AUTOSAR XML (schema 4-0-3)
package /ComponentTypes
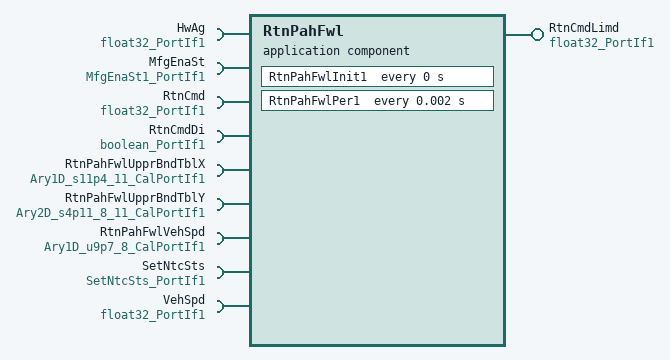
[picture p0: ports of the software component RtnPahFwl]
  application sw component type RtnPahFwl
    provide port RtnCmdLimd: nonqueued-sender-com-spec{data-element=Val, init-value=0}, provided-interface=float32_PortIf1
    9 x require port:
      HwAg: nonqueued-receiver-com-spec{data-element=Val, filter=data-filter-type=ALWAYS, init-value=0}, required-interface=float32_PortIf1
      MfgEnaSt: nonqueued-receiver-com-spec{data-element=Val, filter=data-filter-type=ALWAYS, init-value=0}, required-interface=MfgEnaSt1_PortIf1
      RtnCmd: nonqueued-receiver-com-spec{data-element=Val, filter=data-filter-type=ALWAYS, init-value=0}, required-interface=float32_PortIf1
      RtnCmdDi: nonqueued-receiver-com-spec{data-element=Logl, filter=data-filter-type=ALWAYS, init-value=0}, required-interface=boolean_PortIf1
      RtnPahFwlUpprBndTblX: parameter-require-com-spec{init-value=[-6400, -1600, 0, 800, 1600, 2400, 3200, 4000, 4800, 5600, 6400], parameter=Ary1D}, required-interface=Ary1D_s11p4_11_CalPortIf1
      RtnPahFwlUpprBndTblY: parameter-require-com-spec{init-value=8 x 11 x 18022, parameter=Ary2D}, required-interface=Ary2D_s4p11_8_11_CalPortIf1
      RtnPahFwlVehSpd: parameter-require-com-spec{init-value=[0, 384, 1280, 2560, 3840, 7680, 12800, 32640], parameter=Ary1D}, required-interface=Ary1D_u9p7_8_CalPortIf1
      SetNtcSts: client-com-spec=Oper, required-interface=SetNtcSts_PortIf1
      VehSpd: nonqueued-receiver-com-spec{data-element=Val, filter=data-filter-type=ALWAYS, init-value=0}, required-interface=float32_PortIf1
    behavior RtnPahFwl_InternalBehavior
      ar-typed-per-instance-memorys:
        data dRtnPahFwlLowrBnd: sw-calibration-access=READ-ONLY, type=float32
        data dRtnPahFwlOverBnd: sw-calibration-access=READ-ONLY, type=boolean
        data dRtnPahFwlUpprBnd: sw-calibration-access=READ-ONLY, type=float32
      timing event RtnPahFwlInit1_InitEvent: start-on-event=RtnPahFwlInit1, period=0
      timing event TMT_RtnPahFwlPer1: start-on-event=RtnPahFwlPer1, period=0.002
      runnable RtnPahFwlInit1
        sync call SC_SetNtcSts_Oper: operation=SetNtcSts.Oper, timeout=0
      runnable RtnPahFwlPer1: minimum-start-interval=0.002
        data-receive-point-by-arguments:
          5 x access:
            REC_HwAg_Val: accessed-variable=HwAg.Val
            REC_RtnCmd_Val: accessed-variable=RtnCmd.Val
            REC_RtnCmdDi_Logl: accessed-variable=RtnCmdDi.Logl
            REC_VehSpd_Val: accessed-variable=VehSpd.Val
            SEND_MfgEnaSt_Val: accessed-variable=MfgEnaSt.Val
        data-send-points:
          access SEND_RtnCmdLimd_Val: accessed-variable=RtnCmdLimd.Val
        sync call SC_SetNtcSts_Oper: operation=SetNtcSts.Oper, timeout=0
  swc implementation RtnPahFwl_Implementation: behavior=RtnPahFwl_InternalBehavior
    code-descriptors:
      code Default: artifact-descriptors=autosar-engineering-object={short-label=Default, category=SWSRC}
